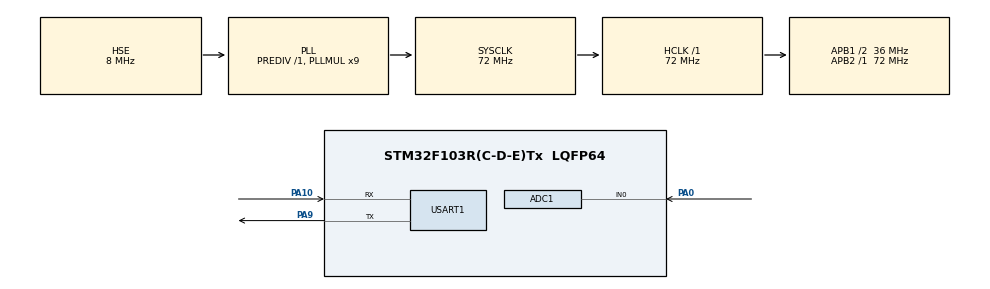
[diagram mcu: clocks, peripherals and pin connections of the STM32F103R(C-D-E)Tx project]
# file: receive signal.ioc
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ADC1.Channel-0\#ChannelRegularConversion=ADC_CHANNEL_0
ADC1.ContinuousConvMode=ENABLE
ADC1.ExternalTrigConv=ADC_SOFTWARE_START
ADC1.NbrOfConversionFlag=1
ADC1.Rank-0\#ChannelRegularConversion=1
ADC1.SamplingTime-0\#ChannelRegularConversion=ADC_SAMPLETIME_55CYCLES_5
ADC1.master=1
Mcu.Family=STM32F1
Mcu.Name=STM32F103R(C-D-E)Tx
Mcu.Package=LQFP64
NVIC.PriorityGroup=NVIC_PRIORITYGROUP_4
NVIC.TIM2_IRQn=true\:0\:0\:false\:false\:true\:true\:true\:true
NVIC.USART1_IRQn=true\:0\:0\:false\:false\:true\:true\:true\:true
PA0-WKUP.Signal=ADCx_IN0
PA10.Mode=Asynchronous
PA10.Signal=USART1_RX
PA13.Mode=Serial_Wire
PA13.Signal=SYS_JTMS-SWDIO
PA14.Mode=Serial_Wire
PA14.Signal=SYS_JTCK-SWCLK
PA9.Mode=Asynchronous
PA9.Signal=USART1_TX
PD0-OSC_IN.Mode=HSE-External-Oscillator
PD0-OSC_IN.Signal=RCC_OSC_IN
PD1-OSC_OUT.Mode=HSE-External-Oscillator
PD1-OSC_OUT.Signal=RCC_OSC_OUT
ProjectManager.HeapSize=0x200
ProjectManager.StackSize=0x400
ProjectManager.TargetToolchain=MDK-ARM V5.32
RCC.ADCPresc=RCC_ADCPCLK2_DIV6
RCC.AHBFreq_Value=72000000
RCC.APB1CLKDivider=RCC_HCLK_DIV2
RCC.APB1Freq_Value=36000000
RCC.APB1TimFreq_Value=72000000
RCC.APB2Freq_Value=72000000
RCC.APB2TimFreq_Value=72000000
RCC.HCLKFreq_Value=72000000
RCC.PLLMUL=RCC_PLL_MUL9
RCC.PLLSourceVirtual=RCC_PLLSOURCE_HSE
RCC.SYSCLKFreq_VALUE=72000000
RCC.SYSCLKSource=RCC_SYSCLKSOURCE_PLLCLK
RCC.USBFreq_Value=72000000
SH.ADCx_IN0.0=ADC1_IN0,IN0
TIM2.AutoReloadPreload=TIM_AUTORELOAD_PRELOAD_ENABLE
TIM2.Period=4000
TIM2.Prescaler=72 - 1
USART1.VirtualMode=VM_ASYNC
VP_TIM2_VS_ClockSourceINT.Mode=Internal
board=custom

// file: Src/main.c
/* USER CODE BEGIN Header */
/**
  ******************************************************************************
  * @file           : main.c
  * @brief          : Main program body
  ******************************************************************************
  * @attention
  *
  * Copyright (c) 2024 STMicroelectronics.
  * All rights reserved.
  *
  * This software is licensed under terms that can be found in the LICENSE file
  * in the root directory of this software component.
  * If no LICENSE file comes with this software, it is provided AS-IS.
  *
  ******************************************************************************
  */
/* USER CODE END Header */
#include "main.h"

/* USER CODE BEGIN Includes */

#include <stdio.h>
#include <stdarg.h>
#include "data_process.h"

/* USER CODE END Includes */

ADC_HandleTypeDef hadc1;

TIM_HandleTypeDef htim2;

UART_HandleTypeDef huart1;

/* USER CODE BEGIN PV */

/* 后面抽象一下串口层 */
void my_uart1_printf(char *format, ...)
{
	unsigned short size;
	unsigned char  String[100];
	va_list arg;
	va_start(arg, format);
	vsprintf((char*)&String, format, arg);
	va_end(arg);

	for (size = 0; String[size] != '\0'; size ++)
	{
		HAL_UART_Transmit(&huart1, (uint8_t *)&String[size], 1, 0xffff);
	}
}

/* USER CODE END PV */

void SystemClock_Config(void);
static void MX_GPIO_Init(void);
static void MX_ADC1_Init(void);
static void MX_USART1_UART_Init(void);
static void MX_TIM2_Init(void);

int main(void)
{

  /* MCU Configuration--------------------------------------------------------*/

  /* Reset of all peripherals, Initializes the Flash interface and the Systick. */
  HAL_Init();

  /* Configure the system clock */
  SystemClock_Config();

  /* Initialize all configured peripherals */
  MX_GPIO_Init();
  MX_ADC1_Init();
  MX_USART1_UART_Init();
  MX_TIM2_Init();
  /* USER CODE BEGIN 2 */

//	HAL_TIM_Base_Start_IT(&htim2);
	//my_uart1_printf("666\n");

  /* USER CODE END 2 */

  /* Infinite loop */
  while (1)
  {

    /* USER CODE BEGIN 3 */
	  uint8_t header[4] = {1, 1, 1, 1};

	  my_uart1_printf("hello uart\n");
//	  if (!header_check(header, 4))
//	  {
//		  uint8_t *bit_info;
//		  bit_info = get_bit_information(4);
//
//		  for (int i = 0; i < 10; i++)
//		  {
//			  my_uart1_printf("%d"    , bit_info[i]);
//		  }
//		  my_uart1_printf("\n");
//	  }
  }
  /* USER CODE END 3 */
}

void SystemClock_Config(void)
{
  RCC_OscInitTypeDef RCC_OscInitStruct = {0};
  RCC_ClkInitTypeDef RCC_ClkInitStruct = {0};
  RCC_PeriphCLKInitTypeDef PeriphClkInit = {0};

  /** Initializes the RCC Oscillators according to the specified parameters
  * in the RCC_OscInitTypeDef structure.
  */
  RCC_OscInitStruct.OscillatorType = RCC_OSCILLATORTYPE_HSE;
  RCC_OscInitStruct.HSEState = RCC_HSE_ON;
  RCC_OscInitStruct.HSEPredivValue = RCC_HSE_PREDIV_DIV1;
  RCC_OscInitStruct.HSIState = RCC_HSI_ON;
  RCC_OscInitStruct.PLL.PLLState = RCC_PLL_ON;
  RCC_OscInitStruct.PLL.PLLSource = RCC_PLLSOURCE_HSE;
  RCC_OscInitStruct.PLL.PLLMUL = RCC_PLL_MUL9;
  if (HAL_RCC_OscConfig(&RCC_OscInitStruct) != HAL_OK)
  {
    Error_Handler();
  }

  /** Initializes the CPU, AHB and APB buses clocks
  */
  RCC_ClkInitStruct.ClockType = RCC_CLOCKTYPE_HCLK|RCC_CLOCKTYPE_SYSCLK
                              |RCC_CLOCKTYPE_PCLK1|RCC_CLOCKTYPE_PCLK2;
  RCC_ClkInitStruct.SYSCLKSource = RCC_SYSCLKSOURCE_PLLCLK;
  RCC_ClkInitStruct.AHBCLKDivider = RCC_SYSCLK_DIV1;
  RCC_ClkInitStruct.APB1CLKDivider = RCC_HCLK_DIV2;
  RCC_ClkInitStruct.APB2CLKDivider = RCC_HCLK_DIV1;

  if (HAL_RCC_ClockConfig(&RCC_ClkInitStruct, FLASH_LATENCY_2) != HAL_OK)
  {
    Error_Handler();
  }
  PeriphClkInit.PeriphClockSelection = RCC_PERIPHCLK_ADC;
  PeriphClkInit.AdcClockSelection = RCC_ADCPCLK2_DIV6;
  if (HAL_RCCEx_PeriphCLKConfig(&PeriphClkInit) != HAL_OK)
  {
    Error_Handler();
  }
}

static void MX_ADC1_Init(void)
{

  ADC_ChannelConfTypeDef sConfig = {0};

  /** Common config
  */
  hadc1.Instance = ADC1;
  hadc1.Init.ScanConvMode = ADC_SCAN_DISABLE;
  hadc1.Init.ContinuousConvMode = ENABLE;
  hadc1.Init.DiscontinuousConvMode = DISABLE;
  hadc1.Init.ExternalTrigConv = ADC_SOFTWARE_START;
  hadc1.Init.DataAlign = ADC_DATAALIGN_RIGHT;
  hadc1.Init.NbrOfConversion = 1;
  if (HAL_ADC_Init(&hadc1) != HAL_OK)
  {
    Error_Handler();
  }

  /** Configure Regular Channel
  */
  sConfig.Channel = ADC_CHANNEL_0;
  sConfig.Rank = ADC_REGULAR_RANK_1;
  sConfig.SamplingTime = ADC_SAMPLETIME_55CYCLES_5;
  if (HAL_ADC_ConfigChannel(&hadc1, &sConfig) != HAL_OK)
  {
    Error_Handler();
  }

}

static void MX_TIM2_Init(void)
{

  TIM_ClockConfigTypeDef sClockSourceConfig = {0};
  TIM_MasterConfigTypeDef sMasterConfig = {0};

  htim2.Instance = TIM2;
  htim2.Init.Prescaler = 72 - 1;
  htim2.Init.CounterMode = TIM_COUNTERMODE_UP;
  htim2.Init.Period = 4000;
  htim2.Init.ClockDivision = TIM_CLOCKDIVISION_DIV1;
  htim2.Init.AutoReloadPreload = TIM_AUTORELOAD_PRELOAD_ENABLE;
  if (HAL_TIM_Base_Init(&htim2) != HAL_OK)
  {
    Error_Handler();
  }
  sClockSourceConfig.ClockSource = TIM_CLOCKSOURCE_INTERNAL;
  if (HAL_TIM_ConfigClockSource(&htim2, &sClockSourceConfig) != HAL_OK)
  {
    Error_Handler();
  }
  sMasterConfig.MasterOutputTrigger = TIM_TRGO_RESET;
  sMasterConfig.MasterSlaveMode = TIM_MASTERSLAVEMODE_DISABLE;
  if (HAL_TIMEx_MasterConfigSynchronization(&htim2, &sMasterConfig) != HAL_OK)
  {
    Error_Handler();
  }

}

static void MX_USART1_UART_Init(void)
{

  huart1.Instance = USART1;
  huart1.Init.BaudRate = 115200;
  huart1.Init.WordLength = UART_WORDLENGTH_8B;
  huart1.Init.StopBits = UART_STOPBITS_1;
  huart1.Init.Parity = UART_PARITY_NONE;
  huart1.Init.Mode = UART_MODE_TX_RX;
  huart1.Init.HwFlowCtl = UART_HWCONTROL_NONE;
  huart1.Init.OverSampling = UART_OVERSAMPLING_16;
  if (HAL_UART_Init(&huart1) != HAL_OK)
  {
    Error_Handler();
  }

}

static void MX_GPIO_Init(void)
{

  /* GPIO Ports Clock Enable */
  __HAL_RCC_GPIOD_CLK_ENABLE();
  __HAL_RCC_GPIOA_CLK_ENABLE();

}

/* USER CODE BEGIN 4 */

/* 记得将这里改成一发布-订阅模式 */

/* USER CODE END 4 */

void Error_Handler(void)
{
  /* USER CODE BEGIN Error_Handler_Debug */
  /* User can add his own implementation to report the HAL error return state */
  __disable_irq();
  while (1)
  {
	  my_uart1_printf("666\n");
  }
  /* USER CODE END Error_Handler_Debug */
}
